# EOS-S3 register map
File version: 0.1
CPU: CM4 r0p1, selectable endian, MPU, FPU, 3 interrupt priority bits
Registers are 32-bit, read-write, reset 0x0 unless marked. A register's access mark holds for its fields unless they carry their own. Offsets are from the block's base; [hi:lo] are bit positions; {n}, {i} and the like mark numbered series.

## SPI — SPI peripheral control
Base 0x40007000
0x00 CTRLR0 21-bit — Control Register 0: This register controls the serial data transfer. It is impossible to write to this register when the SPI Master is enabled. The SPI Master is enabled and disabled by writing to the SSIENR register (0x008).
  [20:16] DFS_32 ro — Data Frame Size in 32-bit mode. Used to select the data frame size in 32-bit mode. These bits are only valid when SSI_MAX_XFER_SIZE is configured to 32. When the data frame size is programmed to be less than 32 bits, the receive data is automatically right-justified by the receive logic, with the upper bits of the receive FIFO zero-padded. You are responsible for making sure the transmit data is right-justified before writing into the transmit FIFO. The transmit logic ignores the upper unused bits when transmitting the data. For the field decode value, refer to Table 6-3 on page 101.
    {v}=word_{v+1}bit ({v+1} bit serial data transfer) (v=3..15)
  [15:12] CFS — Control Frame Size. Selects the length of the control word for the Microwire frame format. For the field decode, refer to Table 6-3 on page 101
    {v}=word_{v+1}bit ({v+1} bit control word) (v=0..15)
  [11] SRL — Shift Register Loop. Used for testing purposes only. When internally active, connects the transmit shift register output to the receive shift register input. Can be used in both serial slave and serial-master modes. When the SPI Master is configured as a slave in loopback mode, the ss_in_n and ssi_clk signals must be provided by an external source. In this mode, the slave cannot generate these signals because there is nothing to which to loop back.
    0=Normal mode operation; 1=Test mode operation
  [10] SLV_OE — No function for SPI Master. Slave usage only.
  [9:8] TMOD — Transfer Mode. Selects the mode of transfer for serial communication. This field does not affect the transfer duplicity. Only indicates whether the receive or transmit data are valid. In transmit-only mode, data received from the external device is not valid and is not stored in the receive FIFO memory; it is overwritten on the next transfer. In receive-only mode, transmitted data are not valid. After the first write to the transmit FIFO, the same word is retransmitted for the duration of the transfer. In transmit-and-receive mode, both transmit and receive data are valid. The transfer continues until the transmit FIFO is empty. Data received from the external device are stored into the receive FIFO memory, where it can be accessed by the host processor. In eeprom-read mode, receive data is not valid while control data is being transmitted. When all control data is sent to the EEPROM, receive data becomes valid and transmit data becomes invalid. All data in the transmit FIFO is considered control data in this mode. This transfer mode is only valid when the SPI Master is configured as a master device.
    0=tx_rx (Transmit and receive); 1=tx (Transmit only); 2=rx (Receive only); 3=EEPROM read
  [7] SCPOL — Serial Clock Polarity. Valid when the frame format (FRF) is set to Motorola SPI. Used to select the polarity of the inactive serial clock, which is held inactive when the SPI Master is not actively transferring data on the serial bus. Dependencies: When SSI_HC_FRF=1, SCPOL bit is a read-only bit with its value set by SSI_DFLT_SCPOL.
    0=inactive_low (Inactive state of serial clock is low); 1=inactive_high (Inactive state of serial clock is high)
  [6] SCPH — Serial Clock Phase. Valid when the frame format (FRF) is set to Motorola SPI. The serial clock phase selects the relationship of the serial clock with the slave select signal. When SCPH = 0, data are captured on the first edge of the serial clock. When SCPH = 1, the serial clock starts toggling one cycle after the slave select line is activated, and data are captured on the second edge of the serial clock. Dependencies: When SSI_HC_FRF=1, SCPH bit is a read-only bit, with its value set by SSI_DFLT_SCPH.
    0=toggle_middle (Serial clock toggles in middle of first data bit); 1=toggle_start (Serial clock toggles at start of first data bit)
  [5:4] FRF — 00 - Motorola SPI only
  [3:0] DFS — Data Frame Size. Dependencies: When SSI_HC_FRF=1, SCPH bit is a read-only bit, with its value set by SSI_DFLT_SCPH. Selects the data frame length. When the data frame size is programmed to be less than 16 bits, the receive data are automatically right-justified by the receive logic, with the upper bits of the receive FIFO zero-padded. You must right-justify transmit data before writing into the transmit FIFO. The transmit logic ignores the upper unused bits when transmitting the data. For the field decode, refer to Table 6-2.
    {v}=word_{v+1}bit ({v+1} bit serial data transfer) (v=3..15)
0x00 DR0 — The SPI Master data register is a 16-bit read/write buffer for the transmit/receive FIFOs. When the register is read, data in the receive FIFO buffer is accessed. When it is written to, data are moved into the transmit FIFO buffer; a write can occur only when SSI_EN = 1. FIFOs are reset when SSI_EN = 0. Please refer to SSIENR register (0x008) to enable and disable the SPI Master. The DR register in the SPI Master occupies 131(for TX)/8(for RX) 32-bit address locations of the memory map to facilitate AHB burst transfers. Writing to any of these address locations has the same effect as pushing the data from the pwdata bus into the transmit FIFO. Reading from any of these locations has the same effect as popping data from the receive FIFO onto the prdata bus. The FIFO buffers on the SPI Master are not addressable.
  [15:0] DR — Data Register. When writing to this register, you must right-justify the data. Read data are automatically right-justified. Read = Receive FIFO buffer (SSI_RX_FIFO_DEPTH = 0x8) Write = Transmit FIFO buffer (SSI_TX_FIFO_DEPTH = 0x83)
0x04 CTRLR1 16-bit — Control Register 1: CTRLR1 register controls the end of serial transfers when in receive-only mode. It is impossible to write to this register when the SPI Master is enabled. The SPI Master is enabled and disabled by writing to the SSIENR register (0x008).
  [15:0] NDF — Number of Data Frames. When TMOD = 10 or TMOD = 11, this register field sets the number of data frames to be continuously received by the SPI Master. The SPI Master continues to receive serial data until the number of data frames received is equal to this register value plus 1, which enables you to receive up to 64 KB of data in a continuous transfer. When the SPI Master is configured as a serial slave, the transfer continues for as long as the slave is selected. Therefore, this register serves no purpose and is not present when the SPI Master is configured as a serial slave.
0x08 SSIENR 1-bit — SSI Enable Register: This register enables and disables the SPI Master. The following SPI Master registers are NOT writeable when SPI Master is enabled =1: CTRLR0, CTRLR1, BAUDR. You must set SSIENR = 0, before writing these 3 registers. The following SPI Master registers are writeable ONLY when the SPI Master is enabled = 1: DR0.
  [0] SSI_EN — SSI Enable. Enables and disables all SPI Master operations. When disabled, all serial transfers are halted immediately. Transmit and receive FIFO buffers are cleared when the device is disabled. It is impossible to program some of the SPI Master control registers when enabled. When disabled, the ssi_sleep output is set (after delay) to inform the system that it is safe to remove the ssi_clk, thus saving power consumption in the system.
0x10 SER 3-bit reset not defined — Slave Enable Register: This register enables the individual slave select output lines from the SPI Master. You cannot write to this register when SPI Master is busy.
  [2] SER_SS3 — Slave 3 Select Enable Flag. When set, the corresponding slave select line from the master is activated when a serial transfer begins. It should be noted that setting or clearing bits in this register have no effect on the corresponding slave select outputs until a transfer is started. Before beginning a transfer, you should enable the bit in this register. When not operating in broadcast mode, only one bit in the register should be set.
  [1] SER_SS2 — Slave 2 Select Enable Flag. When set, the corresponding slave select line from the master is activated when a serial transfer begins. It should be noted that setting or clearing bits in this register have no effect on the corresponding slave select outputs until a transfer is started. Before beginning a transfer, you should enable the bit in this register. When not operating in broadcast mode, only one bit in the register should be set.
  [0] SER_SS1 — Slave 1 Select Enable Flag. When set, the corresponding slave select line from the master is activated when a serial transfer begins. It should be noted that setting or clearing bits in this register have no effect on the corresponding slave select outputs until a transfer is started. Before beginning a transfer, you should enable the bit in this register. When not operating in broadcast mode, only one bit in the register should be set.
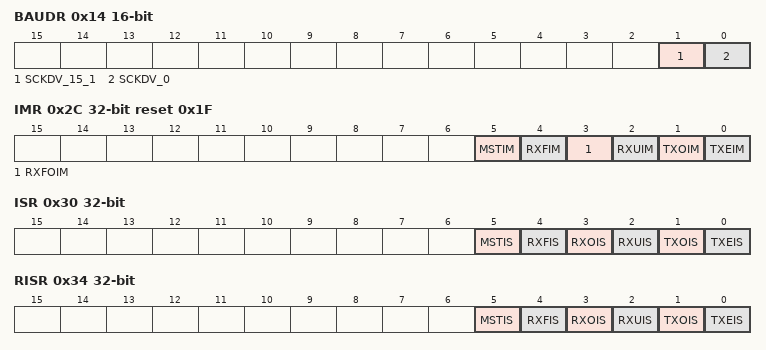
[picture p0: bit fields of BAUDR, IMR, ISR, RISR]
0x14 BAUDR 16-bit — Baud Rate Select Register: This register derives the frequency of the serial clock that regulates the data transfer. It is impossible to write to this register when the SPI Master is enabled. The SPI Master is enabled and disabled by writing the SSIENR register (0x008).
  [1] SCKDV_15_1 — SSI Clock Divider. The LSB for this field is always set to 0 and is unaffected by a write operation, which ensures an even value is held in this register. If the value is 0, the serial output clock (sclk_out) is disabled. The frequency of the sclk_out is derived from the following equation: `Fsclk_out = Fssi_clk/SCKDV` where SCKDV is any even value between 2 and 65534. For example: for `Fssi_clk = 3.6864MHz` and `SCKDV` =2, `Fsclk_out = 3.6864/2 = 1.8432MHz`
  [0] SCKDV_0 ro — From description of `SCKDV_15_1`: 'The LSB for this field is always set to 0 and is unaffected by a write operation, which ensures an even value is held in this register. ' `SCKDV` is broken into `SCK_DV_15_1` and `SCK_DV_0`.
0x18 TXFTLR — Transmit FFIFO Threshold Level Register: This register controls the threshold value for the transmit FIFO memory.
  [7:0] TFT — Transmit FIFO Threshold. Controls the level of entries (or below) at which the transmit FIFO controller triggers an interrupt ssi_txe_intr`. The FIFO depth is configurable in the range 2-256; this register is sized to the number of address bits needed to access the FIFO. If you attempt to set bits [7:0] of this register to a value greater than or equal to the depth of the FIFO, this field is not written and retains its current value. When the number of transmit FIFO entries is less than or equal to this value, the transmit FIFO empty interrupt is triggered. For field decode, refer to Table 6-4.
0x1C RXFTLR — Receive FIFO Threshold Level Register: This register controls the threshold value for the receive FIFO memory.
  [2:0] RFT — Receive FIFO Threshold. Controls the level of entries (or above) at which the receive FIFO controller triggers an interrupt `ssi_rxf_intr`. The FIFO depth is configurable in the range 2-256. This register is sized to the number of address bits needed to access the FIFO. If you attempt to set this value greater than the depth of the FIFO, this field is not written and retains its current value. When the number of receive FIFO entries is greater than or equal to this value + 1, the receive FIFO full interrupt is triggered. For field decode, refer to Table 6-5.
0x20 TXFLR — Transmit FIFO Level Register: This register contains the number of valid data entries in the transmit FIFO memory.
  [2:0] TXTFL ro — Transmit FIFO Level. Contains the number of valid data entries in the transmit FIFO.
0x24 RXFLR — Receive FIFO Level Register: This register contains the number of valid data entries in FIFO memory. This register can be read at any time.
  [2:0] RXTFL ro — Receive FIFO Level. Contains the number of valid data entries in the receive FIFO.
0x28 SR 7-bit — Status Register: This is a read-only register used to indicate the current transfer status, FIFO status, and any transmission/reception errors that may have occurred. This status register may be read at any time. None of the bits in this register request an interrupt.
  [6] DCOL ro — Data Collision Error. Relevant only when the SPI Master is configured as a master device. This bit is set if the SPI Master is actively transmitting when another master selects this device as a slave. This informs the processor that the last data transfer was halted before completion. This bit is cleared when read.
  [5] TXE ro — No function for SPI Master. Slave usage only.
  [4] RFF ro — Receive FIFO Full. When the receive FIFO is completely full, this bit is set. When the receive FIFO contains one or more empty location, this bit is cleared.
  [3] RFNE ro — Receive FIFO Not Empty. Set when the receive FIFO contains one or more entries and is cleared when the receive FIFO is empty. This bit can be polled by software to completely empty the receive FIFO.
  [2] TFE ro — Transmit FIFO Empty. When the transmit FIFO is completely empty, this bit is set. When the transmit FIFO contains one or more valid entries, this bit is cleared. This bit field does not request an interrupt.
  [1] TFNF ro — Transmit FIFO Not Full. Set when the transmit FIFO contains one or more empty locations, and is cleared when the FIFO is full.
  [0] BUSY ro — SSI Busy Flag. When set, indicates that a serial transfer is in progress; when cleared indicates that the SPI Master is idle or disabled.
0x2C IMR reset 0x1F (reset mask 0x1F) — Interrupt Mask Register: This read/write register masks or enables all interrupts generated by the SPI Master.
  [all] fields
    0=Mask the interrupt; 1=Unmask the interrupt
  [5] MSTIM — Multi-Master Contention Interrupt Mask. This bit field is not present if the SPI Master is configured as a serial-slave device.
  [4] RXFIM — Receive FIFO Full Interrupt Mask
  [3] RXFOIM — Receive FIFO Overflow Interrupt Mask
  [2] RXUIM — Receive FIFO Underflow Interrupt Mask
  [1] TXOIM — Transmit FIFO Overflow Interrupt Mask
  [0] TXEIM — Transmit FIFO Empty Interrupt Mask
0x30 ISR — Interrupt Status Register: This register reports the status of SPI Master interrupts after they have been masked.
  [5] MSTIS — Multi-Master Contention Interrupt Status. This bit field is not present if the SPI Master is configured as a serial-slave device.
  [4] RXFIS — Receive FIFO Full Interrupt Status
  [3] RXOIS — Receive FIFO Overflow Interrupt Status
  [2] RXUIS — Receive FIFO Underflow Interrupt Status
  [1] TXOIS — Transmit FIFO Overflow Interrupt Status
  [0] TXEIS — Transmit FIFO Empty Interrupt Status
0x34 RISR — Raw Interrupt Status Register: This read-only register reports the status of the SPI Master interrupts prior to masking.
  [5] MSTIS — Multi-Master Contention Raw Interrupt Status. This bit field is not present if the SPI Master is configured as a serial-slave device.
  [4] RXFIS — Receive FIFO Full Raw Interrupt Status
  [3] RXOIS — Receive FIFO Overflow Raw Interrupt Status
  [2] RXUIS — Receive FIFO Underflow Raw Interrupt Status
  [1] TXOIS — Transmit FIFO Overflow Raw Interrupt Status
  [0] TXEIS — Transmit FIFO Empty Raw Interrupt Status
0x38 TXOICR 1-bit — Transmit FIFO Overflow Interrupt Clear Register.
  [0] TXOICR ro — Clear Transmit FIFO Overflow Interrupt. This register reflects the status of the interrupt. A read from this register clears the ssi_txo_intr interrupt; writing has no effect.
0x3C RXOICR 1-bit — Receive FIFO Overflow Interrupt Clear Register.
  [0] TXOICR ro — Clear Receive FIFO Overflow Interrupt. This register reflects the status of the interrupt. A read from this register clears the ssi_txo_intr interrupt; writing has no effect.
0x40 RXUICR 1-bit — Receive FIFO Underflow Interrupt Clear Register.
  [0] TXOICR ro — Clear Receive FIFO Underflow Interrupt. This register reflects the status of the interrupt. A read from this register clears the ssi_rxu_intr interrupt; writing has no effect.
0x44 MSTICR 1-bit — Multi-Master Interrupt Clear Register.
  [0] TXOICR ro — Clear Multi-Master Contention Interrupt. This register reflects the status of the interrupt. read from this register clears the ssi_mst_intr interrupt; writing has no effect.
0x48 ICR 1-bit — Interrupt Clear Register.
  [0] TXOICR ro — Clear Interrupts. This register is set if any of the interrupts below are active. A read clears the ssi_txo_intr, ssi_rxu_intr, ssi_rxo_intr, and the ssi_mst_intr interrupts. Writing to this register has no effect.
0x58 IDR reset 0xFFFFFFFF — Identification Code. This register contains the peripherals identification code.
  [31:0] IDCODE ro
0x5C SSI_COMP_VERSION reset 0x3332332A — Contains the hex representation of the component version. Consists of ASCII value for each number in the version, followed by *. For example 32_30_31_2A represents the version 2.01*.
